# M2354 register map
File version: 1.0
Registers are 32-bit, read-write, reset 0x0 unless marked. A register's access mark holds for its fields unless they carry their own. Offsets are from the block's base; [hi:lo] are bit positions; {n}, {i} and the like mark numbered series; 'fields as' and 'values as' point back to an identical list.

## NVIC — NVIC Register Map
Base 0xE000E100
{0x0+4i} NVIC_ISER{i} (i=0..2) — IRQ{32i:02} ~ IRQ{32i+31} Set-enable Control Register
  [31:0] SETENA — Interrupt Set Enable Bit. The NVIC_ISER0-NVIC_ISER3 registers enable interrupts, and show which interrupts are enabled. Write Operation:
    0=No effect. Interrupt Disabled; 1=Interrupt Enabled
0x0C NVIC_ISER3 — IRQ96 ~ IRQ115 Set-enable Control Register
  fields as NVIC_ISER0
{0x80+4i} NVIC_ICER{i} (i=0..2) — IRQ{32i:02} ~ IRQ{32i+31} Clear-enable Control Register
  [31:0] CALENA — Interrupt Clear Enable Bit. The NVIC_ICER0-NVIC_ICER3 registers disable interrupts, and show which interrupts are enabled. Write Operation:
    0=No effect. Interrupt Disabled; 1=Interrupt Disabled. Interrupt Enabled
0x8C NVIC_ICER3 — IRQ96 ~ IRQ115 Clear-enable Control Register
  fields as NVIC_ICER0
{0x100+4i} NVIC_ISPR{i} (i=0..2) — IRQ{32i:02} ~ IRQ{32i+31} Set-pending Control Register
  [31:0] SETPEND — Interrupt Set-pending. The NVIC_ISPR0-NVIC_ISPR3 registers force interrupts into the pending state, and show which interrupts are pending. Write Operation:
    0=No effect. Interrupt is not pending; 1=Changes interrupt state to pending. Interrupt is pending
0x10C NVIC_ISPR3 — IRQ96 ~ IRQ115 Set-pending Control Register
  fields as NVIC_ISPR0
0x180 NVIC_ICPR0 — IRQ00 ~ IRQ31 Clear-pending Control Register
  [31:0] CALPEND — Interrupt Clear-pending. The NVIC_ICPR0-NVIC_ICPR3 registers remove the pending state from interrupts, and show which interrupts are pending. Write Operation:
    0=No effect. Interrupt is not pending; 1=Removes pending state an interrupt. Interrupt is pending
0x184 NVIC_ICPR1 — IRQ32 ~ IRQ63 Clear-pending Control Register
  fields as NVIC_ICPR0
0x188 NVIC_ICPR2 — IRQ64 ~ IRQ95 Clear-pending Control Register
  [31:0] CALPEND — Interrupt Clear-pending. The NVIC_ICPR0-NVIC_ICPR3 registers remove the pending state from interrupts, and show which interrupts are pending. Write Operation:
    0=No effect. Interrupt is not pending; 1=Remove pending state an interrupt. Interrupt is pending
0x18C NVIC_ICPR3 — IRQ96 ~ IRQ115 Clear-pending Control Register
  fields as NVIC_ICPR2
0x200 NVIC_IABR0 — IRQ00 ~ IRQ31 Active Bit Register
  [31:0] ACTIVE — Interrupt Active Flags. The NVIC_IABR0-NVIC_IABR3 registers indicate which interrupts are active.
    0=Interrupt not active; 1=Interrupt active
0x204 NVIC_IABR1 — IRQ32 ~ IRQ63 Active Bit Register
  [31:0] ACTIVE — Interrupt Active Flags. The NVIC_IABR0-NVIC_IABR3 registers indicate which interrupts are active.
    0=interrupt not active; 1=interrupt active
0x208 NVIC_IABR2 — IRQ64 ~ IRQ95 Active Bit Register
  fields as NVIC_IABR1
0x20C NVIC_IABR3 — IRQ96 ~ IRQ115 Active Bit Register
  fields as NVIC_IABR1
0x280 NVIC_ITNS0 — IRQ00 ~ IRQ31 Interrupt Target Non-secure Register
  [31:0] ITNS — Interrupt Target Non-secure Register. The NVIC_ITNS0-NVIC_INTS3 registers, determines whether each interrupt targets Non-secure or Secure state. This register is RAZ/WI when accessed as Non-secure.
    0=Interrupt targets Secure state; 1=Interrupt targets Non-secure state
0x284 NVIC_ITNS1 — IRQ32 ~ IRQ63 Interrupt Target Non-secure Register
  [31:0] ITNS — Interrupt Target Non-secure Register. The NVIC_ITNS0-NVIC_INTS3 registers, determines whether each interrupt targets Non-secure or Secure state. Note: This register is RAZ/WI when accessed as Non-secure.
    values as NVIC_ITNS0.ITNS
0x288 NVIC_ITNS2 — IRQ64 ~ IRQ95 Interrupt Target Non-secure Register
  fields as NVIC_ITNS1
0x28C NVIC_ITNS3 — IRQ96 ~ IRQ115 Interrupt Target Non-secure Register
  fields as NVIC_ITNS1
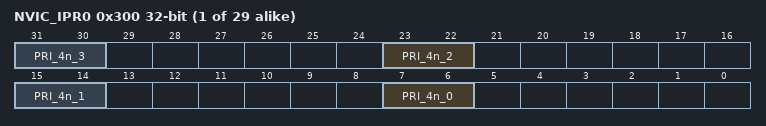
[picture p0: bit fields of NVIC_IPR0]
{0x300+4i} NVIC_IPR{i} (i=0..28) — IRQ0 ~ IRQ115 Priority Control Register
  [8n+7:8n+6] PRI_4n_{n} (n=0..3) — Priority of IRQ_4n+{n} '0' denotes the highest priority and '8' denotes the lowest priority.
